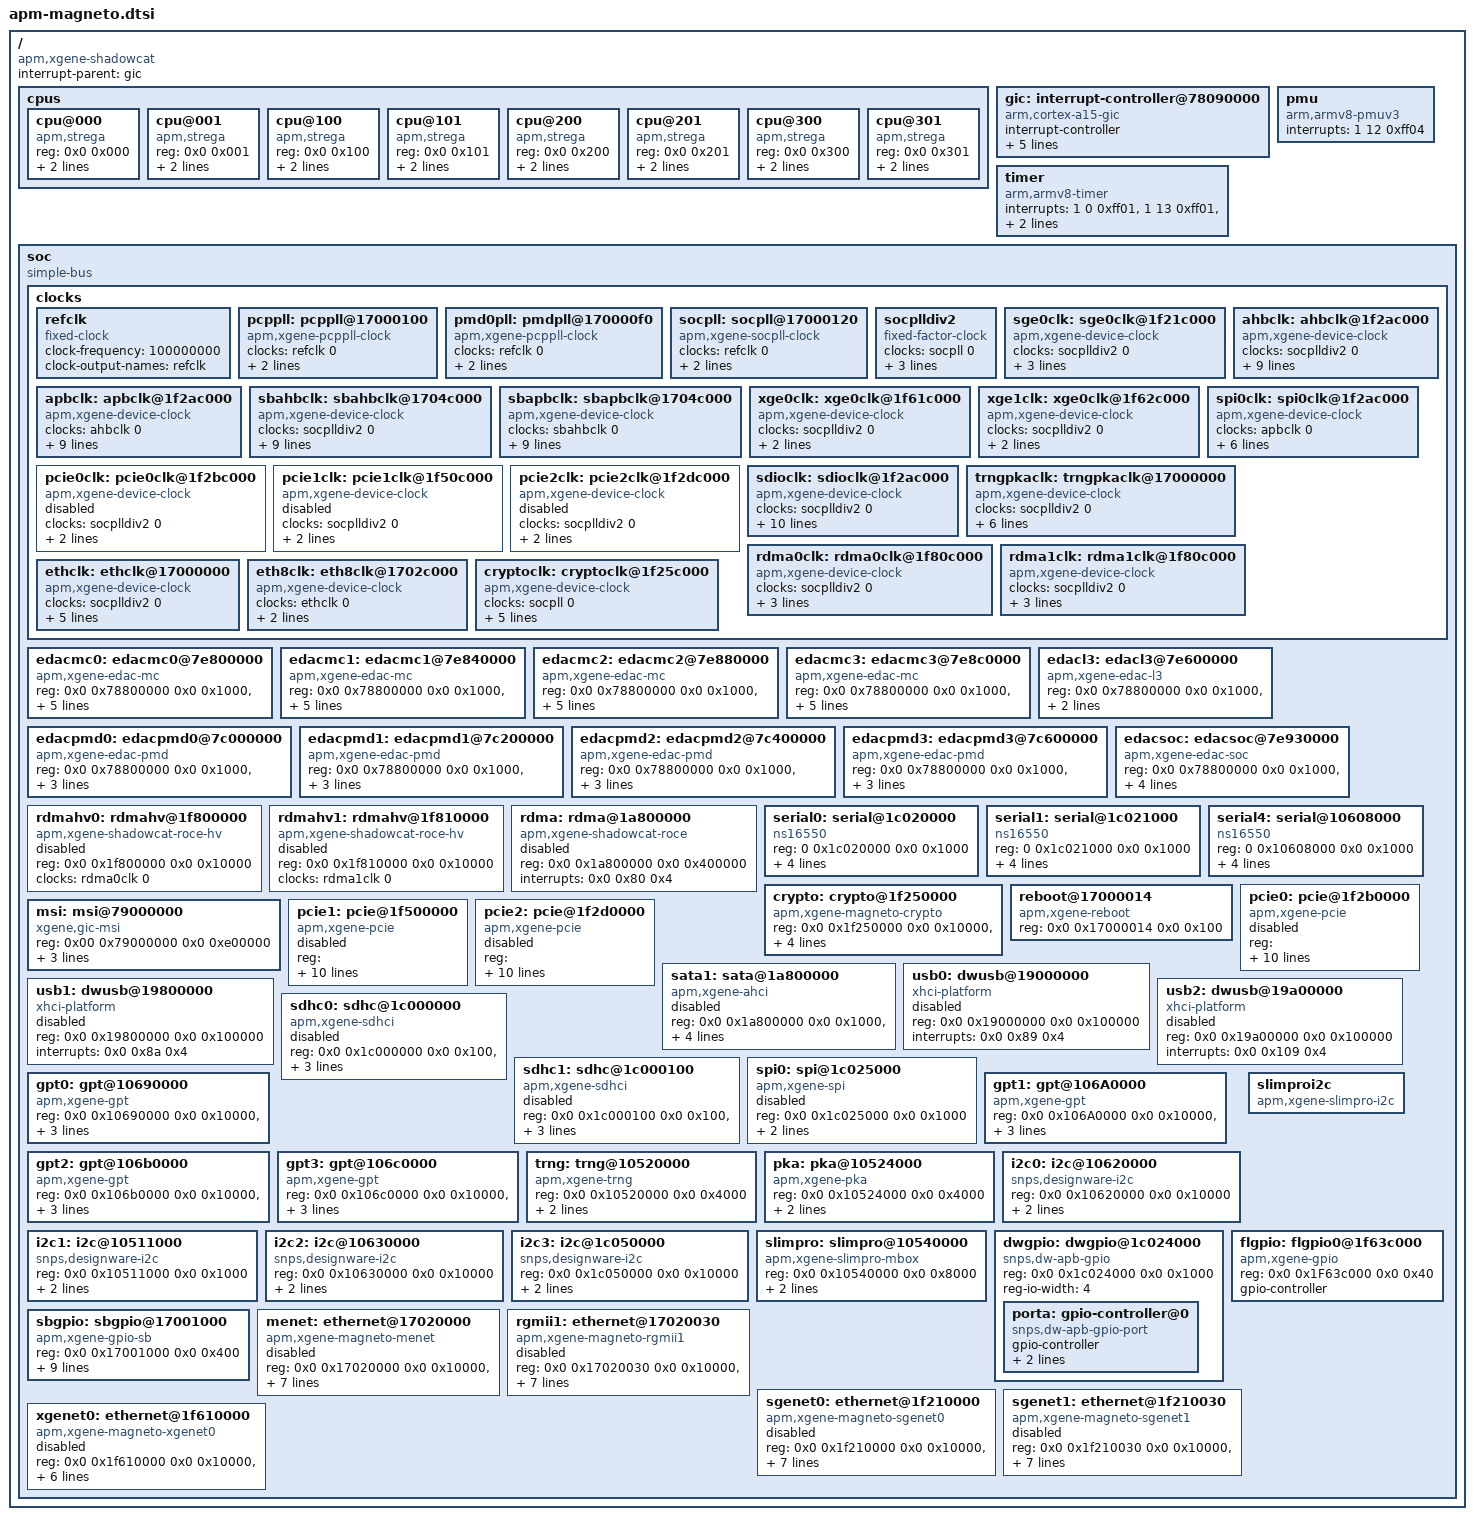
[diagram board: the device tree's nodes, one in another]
/*
 * dts file for AppliedMicro (APM) X-Gene Shadowcat SOC
 *
 * Copyright (C) 2014, Applied Micro Circuits Corporation
 *
 * This program is free software; you can redistribute it and/or
 * modify it under the terms of the GNU General Public License as
 * published by the Free Software Foundation; either version 2 of
 * the License, or (at your option) any later version.
 */

/ {
	compatible = "apm,xgene-shadowcat";
	interrupt-parent = <&gic>;
	#address-cells = <2>;
	#size-cells = <2>;

	cpus {
		#address-cells = <2>;
		#size-cells = <0>;

		cpu@000 {
			device_type = "cpu";
			compatible = "apm,strega", "arm,armv8";
			reg = <0x0 0x000>;
			enable-method = "spin-table";
			cpu-release-addr = <0x1 0x0000fff8>;
		};
		cpu@001 {
			device_type = "cpu";
			compatible = "apm,strega", "arm,armv8";
			reg = <0x0 0x001>;
			enable-method = "spin-table";
			cpu-release-addr = <0x1 0x0000fff8>;
		};
		cpu@100 {
			device_type = "cpu";
			compatible = "apm,strega", "arm,armv8";
			reg = <0x0 0x100>;
			enable-method = "spin-table";
			cpu-release-addr = <0x1 0x0000fff8>;
		};
		cpu@101 {
			device_type = "cpu";
			compatible = "apm,strega", "arm,armv8";
			reg = <0x0 0x101>;
			enable-method = "spin-table";
			cpu-release-addr = <0x1 0x0000fff8>;
		};
		cpu@200 {
			device_type = "cpu";
			compatible = "apm,strega", "arm,armv8";
			reg = <0x0 0x200>;
			enable-method = "spin-table";
			cpu-release-addr = <0x1 0x0000fff8>;
		};
		cpu@201 {
			device_type = "cpu";
			compatible = "apm,strega", "arm,armv8";
			reg = <0x0 0x201>;
			enable-method = "spin-table";
			cpu-release-addr = <0x1 0x0000fff8>;
		};
		cpu@300 {
			device_type = "cpu";
			compatible = "apm,strega", "arm,armv8";
			reg = <0x0 0x300>;
			enable-method = "spin-table";
			cpu-release-addr = <0x1 0x0000fff8>;
		};
		cpu@301 {
			device_type = "cpu";
			compatible = "apm,strega", "arm,armv8";
			reg = <0x0 0x301>;
			enable-method = "spin-table";
			cpu-release-addr = <0x1 0x0000fff8>;
		};
	};

	gic: interrupt-controller@78090000 {
		compatible = "arm,cortex-a15-gic";
		#interrupt-cells = <3>;
		interrupt-controller;
		interrupts = <1 9 0xf04>;	/* GIC Maintenence IRQ */
		reg = <0x0 0x78090000 0x0 0x10000>,	/* GIC Dist */
		      <0x0 0x780A0000 0x0 0x20000>,	/* GIC CPU */
		      <0x0 0x780C0000 0x0 0x10000>,	/* GIC VCPU Control */
		      <0x0 0x780E0000 0x0 0x20000>;	/* GIC VCPU */
	};

	pmu {
		compatible = "arm,armv8-pmuv3";
		interrupts = <1 12 0xff04>;
	};

	timer {
		compatible = "arm,armv8-timer";
		interrupts = <1 0 0xff01>,	/* Secure Phys IRQ */
			     <1 13 0xff01>,	/* Non-secure Phys IRQ */
			     <1 14 0xff01>,	/* Virt IRQ */
			     <1 15 0xff01>;	/* Hyp IRQ */
		clock-frequency = <50000000>;
	};

	soc {
		compatible = "simple-bus";
		#address-cells = <2>;
		#size-cells = <2>;
		ranges;

		clocks {
			#address-cells = <2>;
			#size-cells = <2>;
			ranges;

			refclk: refclk {
				compatible = "fixed-clock";
				#clock-cells = <1>;
				clock-frequency = <100000000>;
				clock-output-names = "refclk";
			};

			pcppll: pcppll@17000100 {
				compatible = "apm,xgene-pcppll-clock";
				#clock-cells = <1>;
				clocks = <&refclk 0>;
				reg = <0x0 0x17000100 0x0 0x1000>;
				clock-output-names = "pcppll";
			};

			pmd0pll: pmdpll@170000f0 {
				compatible = "apm,xgene-pcppll-clock";
				#clock-cells = <1>;
				clocks = <&refclk 0>;
				reg = <0x0 0x170000f0 0x0 0x10>;
				clock-output-names = "pmd0pll";
			};

			socpll: socpll@17000120 {
				compatible = "apm,xgene-socpll-clock";
				#clock-cells = <1>;
				clocks = <&refclk 0>;
				reg = <0x0 0x17000120 0x0 0x1000>;
				clock-output-names = "socpll";
			};

			socplldiv2: socplldiv2  {
				compatible = "fixed-factor-clock";
				#clock-cells = <1>;
				clocks = <&socpll 0>;
				clock-mult = <1>;
				clock-div = <2>;
				clock-output-names = "socplldiv2";
			};

			sge0clk: sge0clk@1f21c000 {
				compatible = "apm,xgene-device-clock";
				#clock-cells = <1>;
				clocks = <&socplldiv2 0>;
				reg = <0x0 0x1f21c000 0x0 0x1000>;
				reg-names = "csr-reg";
				csr-mask = <0x3>;
				clock-output-names = "sge0clk";
			};

			ahbclk: ahbclk@1f2ac000 {
				compatible = "apm,xgene-device-clock";
				#clock-cells = <1>;
				clocks = <&socplldiv2 0>;
				reg = <0x0 0x1f2ac000 0x0 0x1000>;
				reg-names = "csr-reg", "div-reg";
				csr-offset = <0x0>;
				csr-mask = <0x400>;
				enable-offset = <0x8>;
				enable-mask = <0x400>;
				divider-offset = <0x164>;
				divider-width = <0x5>;
				divider-shift = <0x0>;
				clock-output-names = "ahbclk";
			};

			apbclk: apbclk@1f2ac000 {
				compatible = "apm,xgene-device-clock";
				#clock-cells = <1>;
				clocks = <&ahbclk 0>;
				reg = <0x0 0x1f2ac000 0x0 0x1000>;
				reg-names = "csr-reg", "div-reg";
				csr-offset = <0x0>;
				csr-mask = <0x400>;
				enable-offset = <0x8>;
				enable-mask = <0x400>;
				divider-offset = <0x10>;
				divider-width = <0x2>;
				divider-shift = <0x0>;
				clock-output-names = "apbclk";
			};

			sbahbclk: sbahbclk@1704c000 {
				compatible = "apm,xgene-device-clock";
				#clock-cells = <1>;
				clocks = <&socplldiv2 0>;
				reg = <0x0 0x1704c000 0x0 0x1000>;
				reg-names = "csr-reg", "div-reg";
				csr-offset = <0x0>;
				csr-mask = <0x1d>;
				enable-offset = <0x8>;
				enable-mask = <0x1d>;
				divider-offset = <0x164>;
				divider-width = <0x5>;
				divider-shift = <0x0>;
				clock-output-names = "sbahbclk";
                        };

			sbapbclk: sbapbclk@1704c000 {
				compatible = "apm,xgene-device-clock";
				#clock-cells = <1>;
				clocks = <&sbahbclk 0>;
				reg = <0x0 0x1704c000 0x0 0x1000>;
				reg-names = "csr-reg", "div-reg";
				csr-offset = <0x0>;
				csr-mask = <0x1d>;
				enable-offset = <0x8>;
				enable-mask = <0x1d>;
				divider-offset = <0x10>;
				divider-width = <0x2>;
				divider-shift = <0x0>;
				clock-output-names = "sbapbclk";
			};

			xge0clk: xge0clk@1f61c000 {
				compatible = "apm,xgene-device-clock";
				#clock-cells = <1>;
				clocks = <&socplldiv2 0>;
				reg = <0x0 0x1f61c000 0x0 0x1000>;
				reg-names = "csr-reg";
				clock-output-names = "xge0clk";
			};

			xge1clk: xge0clk@1f62c000 {
				compatible = "apm,xgene-device-clock";
				#clock-cells = <1>;
				clocks = <&socplldiv2 0>;
				reg = <0x0 0x1f62c000 0x0 0x1000>;
				reg-names = "csr-reg";
				clock-output-names = "xge1clk";
			};

			spi0clk: spi0clk@1f2ac000 {
				compatible = "apm,xgene-device-clock";
				#clock-cells = <1>;
				clocks = <&apbclk 0>;
				reg = <0x0 0x1f2ac000 0x0 0x1000>;
				reg-names = "csr-reg";
				csr-offset = <0x0>;
				csr-mask = <0x100>;
				enable-offset = <0x8>;
				enable-mask = <0x100>;
				clock-output-names = "spi0clk";
			};

			pcie0clk: pcie0clk@1f2bc000 {
				status = "disabled";
				compatible = "apm,xgene-device-clock";
				#clock-cells = <1>;
				clocks = <&socplldiv2 0>;
				reg = <0x0 0x1f2bc000 0x0 0x1000>;
				reg-names = "csr-reg";
				clock-output-names = "pcie0clk";
			};

			pcie1clk: pcie1clk@1f50c000 {
				status = "disabled";
				compatible = "apm,xgene-device-clock";
				#clock-cells = <1>;
				clocks = <&socplldiv2 0>;
				reg = <0x0 0x1f50c000 0x0 0x1000>;
				reg-names = "csr-reg";
				clock-output-names = "pcie1clk";
			};

			pcie2clk: pcie2clk@1f2dc000 {
				status = "disabled";
				compatible = "apm,xgene-device-clock";
				#clock-cells = <1>;
				clocks = <&socplldiv2 0>;
				reg = <0x0 0x1f2dc000 0x0 0x1000>;
				reg-names = "csr-reg";
				clock-output-names = "pcie2clk";
			};

			sdioclk: sdioclk@1f2ac000 {
				compatible = "apm,xgene-device-clock";
				#clock-cells = <1>;
				clocks = <&socplldiv2 0>;
				reg = <0x0 0x1f2ac000 0x0 0x1000
					0x0 0x17000000 0x0 0x2000>;
				reg-names = "csr-reg", "div-reg";
				csr-offset = <0x0>;
				csr-mask = <0x2>;
				enable-offset = <0x8>;
				enable-mask = <0x2>;
				divider-offset = <0x178>;
				divider-width = <0x8>;
				divider-shift = <0x0>;
				clock-output-names = "sdioclk";
			};

			trngpkaclk: trngpkaclk@17000000 {
				compatible = "apm,xgene-device-clock";
				#clock-cells = <1>;
				clocks = <&socplldiv2 0>;
				reg = <0x0 0x17000000 0x0 0x2000>;
				reg-names = "csr-reg";
				csr-offset = <0xc>;
				csr-mask = <0x10>;
				enable-offset = <0x10>;
				enable-mask = <0x10>;
				clock-output-names = "trngpkaclk";
			};

			rdma0clk: rdma0clk@1f80c000 {
				compatible = "apm,xgene-device-clock";
				#clock-cells = <1>;
				clocks = <&socplldiv2 0>;
				reg = <0x0 0x1f80c000 0x0 0x1000>;
				reg-names = "csr-reg";
				clock-output-names = "rdma0clk";
				enable-offset = <0x4>;
			};

			rdma1clk: rdma1clk@1f80c000 {
				compatible = "apm,xgene-device-clock";
				#clock-cells = <1>;
				clocks = <&socplldiv2 0>;
				reg = <0x0 0x1f81c000 0x0 0x1000>;
				reg-names = "csr-reg";
				clock-output-names = "rdma1clk";
				enable-offset = <0x4>;
			};

			ethclk: ethclk@17000000 {
				compatible = "apm,xgene-device-clock";
				#clock-cells = <1>;
				clocks = <&socplldiv2 0>;
				reg = <0x0 0x17000000 0x0 0x1000>;
				reg-names = "div-reg";
				divider-offset = <0x238>;
				divider-width = <0x9>;
				divider-shift = <0x0>;
				clock-output-names = "ethclk";
			};

			eth8clk: eth8clk@1702c000 {
				compatible = "apm,xgene-device-clock";
				#clock-cells = <1>;
				clocks = <&ethclk 0>;
				reg = <0x0 0x1702c000 0x0 0x1000>;
				reg-names = "csr-reg"; clock-output-names = "eth8clk";
			};

			cryptoclk: cryptoclk@1f25c000 {
				compatible = "apm,xgene-device-clock";
				#clock-cells = <1>;
				clocks = <&socpll 0>;
				reg = <0x0 0x1f25c000 0x0 0x1000
					0x0 0x17000000 0x0 0x2000>;
				reg-names = "csr-reg", "div-reg";
				csr-offset = <0x8>;
				csr-mask = <0x1F>;
				clock-output-names = "cryptoclk";
			};
		};

		edacmc0: edacmc0@7e800000 {
			compatible = "apm,xgene-edac-mc";
			reg =  <0x0 0x78800000 0x0 0x1000>,
			       <0x0 0x7e200000 0x0 0x1000>,
			       <0x0 0x7e700000 0x0 0x1000>,
			       <0x0 0x7e720000 0x0 0x1000>,
			       <0x0 0x7e800000 0x0 0x1000>;
			interrupts = <0x0 0x20 0x4>,
				     <0x0 0x21 0x4>;
		};

		edacmc1: edacmc1@7e840000 {
			compatible = "apm,xgene-edac-mc";
			reg =  <0x0 0x78800000 0x0 0x1000>,
			       <0x0 0x7e200000 0x0 0x1000>,
			       <0x0 0x7e700000 0x0 0x1000>,
			       <0x0 0x7e720000 0x0 0x1000>,
			       <0x0 0x7e840000 0x0 0x1000>;
			interrupts = <0x0 0x20 0x4>,
				     <0x0 0x21 0x4>;
		};

		edacmc2: edacmc2@7e880000 {
			compatible = "apm,xgene-edac-mc";
			reg =  <0x0 0x78800000 0x0 0x1000>,
			       <0x0 0x7e200000 0x0 0x1000>,
			       <0x0 0x7e700000 0x0 0x1000>,
			       <0x0 0x7e720000 0x0 0x1000>,
			       <0x0 0x7e880000 0x0 0x1000>;
			interrupts = <0x0 0x20 0x4>,
				     <0x0 0x21 0x4>;
		};

		edacmc3: edacmc3@7e8c0000 {
			compatible = "apm,xgene-edac-mc";
			reg =  <0x0 0x78800000 0x0 0x1000>,
			       <0x0 0x7e200000 0x0 0x1000>,
			       <0x0 0x7e700000 0x0 0x1000>,
			       <0x0 0x7e720000 0x0 0x1000>,
			       <0x0 0x7e8c0000 0x0 0x1000>;
			interrupts = <0x0 0x20 0x4>,
				     <0x0 0x21 0x4>;
		};

		edacl3: edacl3@7e600000 {
			compatible = "apm,xgene-edac-l3";
			reg =  <0x0 0x78800000 0x0 0x1000>,
			       <0x0 0x7e600000 0x0 0x1000>;
			interrupts = <0x0 0x20 0x4>,
				     <0x0 0x21 0x4>;
		};

		edacpmd0: edacpmd0@7c000000 {
			compatible = "apm,xgene-edac-pmd";
			reg =  <0x0 0x78800000 0x0 0x1000>,
			       <0x0 0x7c000000 0x0 0x200000>,
			       <0x0 0x1054a000 0x0 0x10>;
			interrupts = <0x0 0x20 0x4>,
				     <0x0 0x21 0x4>;
		};

		edacpmd1: edacpmd1@7c200000 {
			compatible = "apm,xgene-edac-pmd";
			reg =  <0x0 0x78800000 0x0 0x1000>,
			       <0x0 0x7c200000 0x0 0x200000>,
			       <0x0 0x1054a000 0x0 0x10>;
			interrupts = <0x0 0x20 0x4>,
				     <0x0 0x21 0x4>;
		};

		edacpmd2: edacpmd2@7c400000 {
			compatible = "apm,xgene-edac-pmd";
			reg =  <0x0 0x78800000 0x0 0x1000>,
			       <0x0 0x7c400000 0x0 0x200000>,
			       <0x0 0x1054a000 0x0 0x10>;
			interrupts = <0x0 0x20 0x4>,
				     <0x0 0x21 0x4>;
		};

		edacpmd3: edacpmd3@7c600000 {
			compatible = "apm,xgene-edac-pmd";
			reg =  <0x0 0x78800000 0x0 0x1000>,
			       <0x0 0x7c600000 0x0 0x200000>,
			       <0x0 0x1054a000 0x0 0x10>;
			interrupts = <0x0 0x20 0x4>,
				     <0x0 0x21 0x4>;
		};

		edacsoc: edacsoc@7e930000 {
			compatible = "apm,xgene-edac-soc";
			reg =  <0x0 0x78800000 0x0 0x1000>,
			       <0x0 0x7e930000 0x0 0x1000>,
                               <0x0 0x7e000000 0x0 0x1000>;
			interrupts = <0x0 0x20 0x4>,
				     <0x0 0x21 0x4>,
				     <0x0 0x27 0x4>;
		};

		rdmahv0: rdmahv@1f800000 {
			status = "disabled";
			compatible = "apm,xgene-shadowcat-roce-hv";
			reg = <0x0 0x1f800000 0x0 0x10000>;
			clocks = <&rdma0clk 0>;
		};

		rdmahv1: rdmahv@1f810000 {
			status = "disabled";
			compatible = "apm,xgene-shadowcat-roce-hv";
			reg = <0x0 0x1f810000 0x0 0x10000>;
			clocks = <&rdma1clk 0>;
		};

		rdma: rdma@1a800000 {
			status = "disabled";
			compatible = "apm,xgene-shadowcat-roce";
			reg = <0x0 0x1a800000 0x0 0x400000>;
			interrupts = <0x0 0x80 0x4>;
		};

		serial0: serial@1c020000 {
			device_type = "serial";
			compatible = "ns16550";
			reg = <0 0x1c020000 0x0 0x1000>;
			reg-shift = <2>;
			clock-frequency = <50000000>;
			interrupt-parent = <&gic>;
			interrupts = <0x0 0x4c 0x4>;
		};

		serial1: serial@1c021000 {
			device_type = "serial";
			compatible = "ns16550";
			reg = <0 0x1c021000 0x0 0x1000>;
			reg-shift = <2>;
			clock-frequency = <50000000>;
			interrupt-parent = <&gic>;
			interrupts = <0x0 0x4d 0x4>;
		};

		serial4: serial@10608000 {
			device_type = "serial";
			compatible = "ns16550";
			reg = <0 0x10608000 0x0 0x1000>;
			reg-shift = <2>;
			clock-frequency = <50000000>;
			interrupt-parent = <&gic>;
			interrupts = <0x0 0x105 0x4>;
		};


		crypto: crypto@1f250000 {
			device_type = "crypto";
			compatible = "apm,xgene-magneto-crypto";
			status = "ok";
			reg = <0x0 0x1f250000 0x0 0x10000>,
			      <0x0 0x1f200000 0x0 0X10000>,
			      <0x0 0x20300000 0x0 0x40000>;
			clocks = <&cryptoclk 0>;
			interrupts = <0x0 0x85 0x4>,
						 <0x0 0x78 0x4>;
		};

		reboot@17000014 {
			compatible = "apm,xgene-reboot";
			reg = <0x0 0x17000014 0x0 0x100>;
		};

		msi: msi@79000000 {
			compatible = "xgene,gic-msi";
			reg = <0x00 0x79000000 0x0 0xe00000>;
			msi-available-ranges = <0x0 0x1000>;
			interrupts = <  0x0 0x120 0x4
					0x0 0x121 0x4
					0x0 0x122 0x4
					0x0 0x123 0x4
					0x0 0x124 0x4
					0x0 0x125 0x4
					0x0 0x126 0x4
					0x0 0x127 0x4
					0x0 0x128 0x4
					0x0 0x129 0x4
					0x0 0x12a 0x4
					0x0 0x12b 0x4
					0x0 0x12c 0x4
					0x0 0x12d 0x4
					0x0 0x12e 0x4
					0x0 0x12f 0x4>;
		};

		pcie0: pcie@1f2b0000 {
			status = "disabled";
			device_type = "pci";
			compatible = "apm,xgene-pcie";
			#interrupt-cells = <1>;
			#size-cells = <2>;
			#address-cells = <3>;
			reg = < 0x00 0x1f2b0000 0x0 0x00010000   /* Controller registers */
				0xe0 0xd0000000 0x0 0x00200000 /* PCI config space */
				0x00 0x79e00000 0x0 0x2000000 /* MSI Generation used only for msi test*/
				0x00 0x79000000 0x0 0x800000>; /* MSI Termination used only for msi test*/
			reg-names = "csr", "cfg", "msi_gen", "msi_term";
			ranges = <0x01000000 0x00 0x00000000 0xe0 0x00000000 0x00 0x00010000   /* io */
				  0x02000000 0x00 0x80000000 0xe1 0x80000000 0x00 0x80000000>; /* mem */
			ib-ranges = <0x02000000 0x80 0x00000000 0x80 0x00000000 0x00 0x80000000 /* BAR 0 */
				     0x02000000 0x00 0x00000000 0x00 0x00000000 0x80 0x00000000>; /* IBAR 3 */

			interrupt-map-mask = <0x0 0x0 0x0 0x7>;
			interrupt-map = <0x0 0x0 0x0 0x1 &gic 0x0 0x0 0x0 0xc2 0x1
					 0x0 0x0 0x0 0x2 &gic 0x0 0x0 0x0 0xc3 0x1
					 0x0 0x0 0x0 0x3 &gic 0x0 0x0 0x0 0xc4 0x1
					 0x0 0x0 0x0 0x4 &gic 0x0 0x0 0x0 0xc5 0x1>;
			clocks = <&pcie0clk 0>;
		};

		pcie1: pcie@1f500000 {
			status = "disabled";
			device_type = "pci";
			compatible = "apm,xgene-pcie";
			#interrupt-cells = <1>;
			#size-cells = <2>;
			#address-cells = <3>;
			reg = < 0x00 0x1f500000 0x0 0x00010000   /* Controller registers */
				0xa0 0xd0000000 0x0 0x00200000 /* PCI config space */
				0x00 0x79e00000 0x0 0x2000000 /* MSI Generation used only for msi test*/
				0x00 0x79000000 0x0 0x800000>; /* MSI Termination used only for msi test*/
			reg-names = "csr", "cfg", "msi_gen", "msi_term";
			ranges = <0x01000000 0x0 0x00000000 0xa0 0x00000000 0x00 0x00010000   /* io  */
				  0x02000000 0x0 0x80000000 0xa1 0x80000000 0x00 0x80000000>; /* mem */
			ib-ranges = <0x02000000 0x80 0x00000000 0x80 0x00000000 0x00 0x80000000 /* BAR 0 */
				     0x02000000 0x00 0x00000000 0x00 0x00000000 0x80 0x00000000>; /* IBAR 3 */
			interrupt-map-mask = <0x0 0x0 0x0 0x7>;
			interrupt-map = <0x0 0x0 0x0 0x1 &gic 0x0 0x0 0x0 0xd4 0x1
					 0x0 0x0 0x0 0x2 &gic 0x0 0x0 0x0 0xd5 0x1
					 0x0 0x0 0x0 0x3 &gic 0x0 0x0 0x0 0xd6 0x1
					 0x0 0x0 0x0 0x4 &gic 0x0 0x0 0x0 0xd7 0x1>;
			clocks = <&pcie1clk 0>;
		};

		pcie2: pcie@1f2d0000 {
			status = "disabled";
			device_type = "pci";
			compatible = "apm,xgene-pcie";
			#interrupt-cells = <1>;
			#size-cells = <2>;
			#address-cells = <3>;
			reg = < 0x00 0x1f2d0000 0x0 0x00010000   /* Controller registers */
				0x90 0xd0000000 0x0 0x00200000 /* PCI config space */
				0x00 0x79e00000 0x0 0x2000000 /* MSI Generation used only for msi test*/
				0x00 0x79000000 0x0 0x800000>; /* MSI Termination used only for msi test*/
			reg-names = "csr", "cfg", "msi_gen", "msi_term";
			ranges = <0x01000000 0x0 0x00000000 0x90 0x00000000 0x00 0x00010000   /* io  */
				  0x02000000 0x0 0x80000000 0x91 0x80000000 0x00 0x80000000>; /* mem */
			ib-ranges = <0x02000000 0x80 0x00000000 0x80 0x00000000 0x00 0x80000000 /* BAR 0 */
				     0x02000000 0x00 0x00000000 0x00 0x00000000 0x80 0x00000000>; /* IBAR 3 */
			interrupt-map-mask = <0x00 0x0 0x0 0x7>;
			interrupt-map = <0x000 0x0 0x0 0x1 &gic 0x0 0x0 0x0 0xce 0x1
					 0x000 0x0 0x0 0x2 &gic 0x0 0x0 0x0 0xcf 0x1
					 0x000 0x0 0x0 0x3 &gic 0x0 0x0 0x0 0xd0 0x1
					 0x000 0x0 0x0 0x4 &gic 0x0 0x0 0x0 0xd1 0x1>;
			clocks = <&pcie2clk 0>;
		};

		sata1: sata@1a800000 {
			compatible = "apm,xgene-ahci";
			reg = <0x0 0x1a800000 0x0 0x1000>,
			      <0x0 0x1f23000 0x0 0x1000>,
			      <0x0 0x1f23d000 0x0 0x1000>,
			      <0x0 0x1f23e000 0x0 0x1000>;
			interrupts = <0x0 0x86 0x4>;
			status = "disabled";
		};

		usb0: dwusb@19000000 {
			status = "disabled";
			compatible = "xhci-platform";
			reg =  <0x0 0x19000000 0x0 0x100000>;
			interrupts = <0x0 0x89 0x4>;
		};

		usb1: dwusb@19800000 {
			status = "disabled";
			compatible = "xhci-platform";
			reg =  <0x0 0x19800000 0x0 0x100000>;
			interrupts = <0x0 0x8a 0x4>;
		};

		usb2: dwusb@19a00000 {
			status = "disabled";
			compatible = "xhci-platform";
			reg =  <0x0 0x19a00000 0x0 0x100000>;
			interrupts = <0x0 0x109 0x4>;
		};

		sdhc0: sdhc@1c000000 {
			status = "disabled";
			device_type = "sdhc";
			compatible = "apm,xgene-sdhci";
			reg = <0x0 0x1c000000 0x0 0x100>,
			      <0x0 0x1f2a0000 0x0 0x1000>;
			interrupts = <0x0 0x49 0x4>;
			#clock-cells = <1>;
			clocks = <&sdioclk 0>;
		};

		sdhc1: sdhc@1c000100 {
			status = "disabled";
			device_type = "sdhc";
			compatible = "apm,xgene-sdhci";
			reg = <0x0 0x1c000100 0x0 0x100>,
			      <0x0 0x1f2a0000 0x0 0x1000>;
			interrupts = <0x0 0x49 0x4>;
			#clock-cells = <1>;
			clocks = <&sdioclk 0>;
		};

		spi0: spi@1c025000 {
			status = "disabled";
			device_type = "spi";
			compatible = "apm,xgene-spi";
			#address-cells = <1>;
			#size-cells = <0>;
			reg = <0x0 0x1c025000 0x0 0x1000>;
			bus_num = <0>;
			#clock-cells = <1>;
			clocks = <&spi0clk 0>;
		};

		gpt0: gpt@10690000 {
			device_type = "gpt";
			compatible = "apm,xgene-gpt";
			#address-cells = <1>;
			#size-cells = <0>;
			reg = <0x0 0x10690000 0x0 0x10000>,
			      <0x0 0x10680000 0x0 0x1000>;
			interrupts = <0x0 0x101 0x4>;
			#clock-cells = <1>;
			clocks = <&sbapbclk 0>; 
		};

		gpt1: gpt@106A0000 {
			device_type = "gpt";
			compatible = "apm,xgene-gpt";
			#address-cells = <1>;
			#size-cells = <0>;
			reg = <0x0 0x106A0000 0x0 0x10000>,
			      <0x0 0x10680000 0x0 0x1000>;
			interrupts = <0x0 0x102 0x4>;
			#clock-cells = <1>;
			clocks = <&sbapbclk 0>;
		};

		gpt2: gpt@106b0000 { 
			device_type = "gpt";
			compatible = "apm,xgene-gpt";
			#address-cells = <1>;
			#size-cells = <0>;
			reg = <0x0 0x106b0000 0x0 0x10000>,
			      <0x0 0x10680000 0x0 0x1000>;
			interrupts = <0x0 0x103 0x4>;
			#clock-cells = <1>;
			clocks = <&sbapbclk 0>;
		};

		gpt3: gpt@106c0000 { 
			device_type = "gpt";
			compatible = "apm,xgene-gpt";
			#address-cells = <1>;
			#size-cells = <0>;
			reg = <0x0 0x106c0000 0x0 0x10000>,
			      <0x0 0x10680000 0x0 0x1000>;
			interrupts = <0x0 0x104 0x4>;
			#clock-cells = <1>;
			clocks = <&sbapbclk 0>;
		};

		trng: trng@10520000 {
			device_type = "trng";
			compatible = "apm,xgene-trng";
			reg = <0x0 0x10520000 0x0 0x4000>;
			interrupts =   <0x0 0x41 0x4
					0x0 0x42 0x4>;
			#clock-cells = <1>;
			clocks = <&trngpkaclk 0>;
		};

		pka: pka@10524000 {
			device_type = "pka";
			compatible = "apm,xgene-pka";
			reg = <0x0 0x10524000 0x0 0x4000>;
			interrupts = <0x0 0x43 0x4>;
			#clock-cells = <1>;
			clocks = <&trngpkaclk 0>;
		};

 		i2c0: i2c@10620000 {
			#address-cells = <1>;
			#size-cells = <0>;
			compatible = "snps,designware-i2c";
			reg = <0x0 0x10620000 0x0 0x10000>;
			interrupts = <0 0x44 0x4>;
			#clock-cells = <1>;
			clocks = <&sbapbclk 0>;
		};

		i2c1: i2c@10511000 {
			#address-cells = <1>;
			#size-cells = <0>;
			compatible = "snps,designware-i2c";
			reg = <0x0 0x10511000 0x0 0x1000>;
			interrupts = <0 0x45 0x4>;
			#clock-cells = <1>;
			clocks = <&sbapbclk 0>;
		};
		
		i2c2: i2c@10630000 {
                        #address-cells = <1>;
                        #size-cells = <0>;
                        compatible = "snps,designware-i2c";
                        reg = <0x0 0x10630000 0x0 0x10000>;
                        interrupts = <0 0x106 0x4>;
                        #clock-cells = <1>;
                        clocks = <&sbapbclk 0>;
                };

		i2c3: i2c@1c050000 {
			#address-cells = <1>;
			#size-cells = <0>;
			compatible = "snps,designware-i2c";
			reg = <0x0 0x1c050000 0x0 0x10000>;
			interrupts = <0 0x107 0x4>;
			#clock-cells = <1>;
			clocks = <&apbclk 0>;
		};

		slimpro: slimpro@10540000 {
			compatible = "apm,xgene-slimpro-mbox";
			reg = <0x0 0x10540000 0x0 0x8000>;
			interrupts =   <0x0 0x0 0x4
					0x0 0x1 0x4
					0x0 0x2 0x4
					0x0 0x3 0x4
					0x0 0x4 0x4
					0x0 0x5 0x4
					0x0 0x6 0x4
					0x0 0x7 0x4>;
		};

		slimproi2c: slimproi2c {
			compatible = "apm,xgene-slimpro-i2c";
		};

		dwgpio: dwgpio@1c024000 {
			compatible = "snps,dw-apb-gpio";
			reg = <0x0 0x1c024000 0x0 0x1000>;
			#address-cells = <1>;
			#size-cells = <0>;
			reg-io-width = <4>;

			porta: gpio-controller@0 {
				compatible = "snps,dw-apb-gpio-port";
				gpio-controller;
				snps,nr-gpios = <32>;
				reg = <0>;
			};
		};

		flgpio: flgpio0@1f63c000 {
			compatible = "apm,xgene-gpio";
			reg = <0x0 0x1F63c000 0x0 0x40>;
			gpio-controller;
			#gpio-cells = <2>;
		};

		sbgpio: sbgpio@17001000{
			compatible = "apm,xgene-gpio-sb";
			reg = <0x0 0x17001000 0x0 0x400>;
			#gpio-cells = <2>;
			ngpio =<18>;
			nirq =<8>;
			irq_pins =<0x08 0x09 0x0A 0x0B 0x0C 0x0D 0x0E 0x0F>;
			gpio-controller;
			#clock-cells = <1>;
			interrupt-parent = <&gic>;
			interrupts = 	<0x0 0x28 0x1>,
					<0x0 0x29 0x1>,
					<0x0 0x2a 0x1>,
					<0x0 0x2b 0x1>,
					<0x0 0x2c 0x1>,
					<0x0 0x2d 0x1>,
					<0x0 0x2e 0x1>,
					<0x0 0x2f 0x1>;
		};

		menet: ethernet@17020000 {
			compatible = "apm,xgene-magneto-menet";
			status = "disabled";
			reg = <0x0 0x17020000 0x0 0x10000>,
			      <0x0 0x1f200000 0x0 0xd100>,
			      <0x0 0x20180000 0x0 0x80000>;
			interrupts = <0 112 4>;
			clocks = <&eth8clk 0>;
			local-mac-address = [00 01 73 00 00 01];
			phy-addr = <5>;
			phy-mode = "rgmii";
		};

		rgmii1: ethernet@17020030 {
			compatible = "apm,xgene-magneto-rgmii1";
			status = "disabled";
			reg = <0x0 0x17020030 0x0 0x10000>,
			      <0x0 0x1f200000 0x0 0xd100>,
			      <0x0 0x20200000 0x0 0x80000>;
			interrupts = <0 114 4>;
			clocks = <&eth8clk 0>;
			local-mac-address = [00 01 73 00 00 02];
			phy-addr = <6>;
			phy-mode = "rgmii";
		};

		sgenet0: ethernet@1f210000 {
			compatible = "apm,xgene-magneto-sgenet0";
			status = "disabled";
			reg = <0x0 0x1f210000 0x0 0x10000>,
			      <0x0 0x1f200000 0x0 0x10000>,
			      <0x0 0x20080000 0x0 0x80000>,
			      <0x0 0x1f615000 0x0 0x10000>;
			interrupts = <0 104 4>;
			clocks = <&sge0clk 0>;
			local-mac-address = [00 01 73 00 00 03];
			phy-mode = "sgmii";
		};

		sgenet1: ethernet@1f210030 {
			compatible = "apm,xgene-magneto-sgenet1";
			status = "disabled";
			reg = <0x0 0x1f210030 0x0 0x10000>,
			      <0x0 0x1f200000 0x0 0x10000>,
			      <0x0 0x20100000 0x0 0x80000>,
			      <0x0 0x1f615000 0x0 0x10000>;
			interrupts = <0x0 108 0x4>;
			clocks = <&sge0clk 0>;
			local-mac-address = [00 01 73 00 00 04];
			phy-mode = "sgmii";
		};

		xgenet0: ethernet@1f610000 {
			compatible = "apm,xgene-magneto-xgenet0";
			status = "disabled";
			reg = <0x0 0x1f610000 0x0 0x10000>,
			      <0x0 0x1f200000 0x0 0x10000>,
			      <0x0 0x20000000 0x0 0x80000>,
			      <0x0 0x1f615000 0x0 0x10000>;
			interrupts = <0x0 0x60 0x4>;
			clocks = <&xge0clk 0>;
			local-mac-address = [00 01 73 00 00 05];
		};

	};
};
